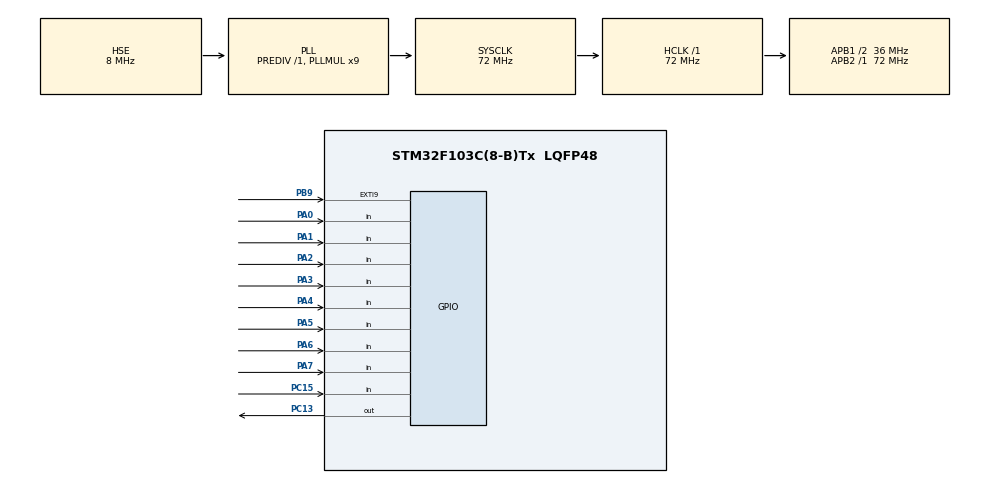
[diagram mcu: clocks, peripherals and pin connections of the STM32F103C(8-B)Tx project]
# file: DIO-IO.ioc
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Mcu.Family=STM32F1
Mcu.Name=STM32F103C(8-B)Tx
Mcu.Package=LQFP48
NVIC.EXTI9_5_IRQn=true\:0\:0\:false\:false\:true\:true\:true\:true
NVIC.PriorityGroup=NVIC_PRIORITYGROUP_4
PA0-WKUP.GPIO_PuPd=GPIO_PULLDOWN
PA0-WKUP.Signal=GPIO_Input
PA1.GPIO_PuPd=GPIO_PULLDOWN
PA1.Signal=GPIO_Input
PA13.Mode=Serial_Wire
PA13.Signal=SYS_JTMS-SWDIO
PA14.Mode=Serial_Wire
PA14.Signal=SYS_JTCK-SWCLK
PA2.GPIO_PuPd=GPIO_PULLDOWN
PA2.Signal=GPIO_Input
PA3.GPIO_PuPd=GPIO_PULLDOWN
PA3.Signal=GPIO_Input
PA4.GPIO_PuPd=GPIO_PULLDOWN
PA4.Signal=GPIO_Input
PA5.GPIO_PuPd=GPIO_PULLDOWN
PA5.Signal=GPIO_Input
PA6.GPIO_PuPd=GPIO_PULLDOWN
PA6.Signal=GPIO_Input
PA7.GPIO_PuPd=GPIO_PULLDOWN
PA7.Signal=GPIO_Input
PB9.GPIO_ModeDefaultEXTI=GPIO_MODE_IT_RISING
PB9.GPIO_PuPd=GPIO_PULLDOWN
PB9.Signal=GPXTI9
PC13-TAMPER-RTC.GPIO_PuPd=GPIO_NOPULL
PC13-TAMPER-RTC.Signal=GPIO_Output
PC15-OSC32_OUT.GPIO_PuPd=GPIO_PULLDOWN
PC15-OSC32_OUT.Signal=GPIO_Input
PD0-OSC_IN.Mode=HSE-External-Oscillator
PD0-OSC_IN.Signal=RCC_OSC_IN
PD1-OSC_OUT.Mode=HSE-External-Oscillator
PD1-OSC_OUT.Signal=RCC_OSC_OUT
ProjectManager.HeapSize=0x200
ProjectManager.StackSize=0x400
ProjectManager.TargetToolchain=CMake
RCC.AHBFreq_Value=72000000
RCC.APB1CLKDivider=RCC_HCLK_DIV2
RCC.APB1Freq_Value=36000000
RCC.APB1TimFreq_Value=72000000
RCC.APB2Freq_Value=72000000
RCC.APB2TimFreq_Value=72000000
RCC.HCLKFreq_Value=72000000
RCC.PLLMUL=RCC_PLL_MUL9
RCC.PLLSourceVirtual=RCC_PLLSOURCE_HSE
RCC.SYSCLKFreq_VALUE=72000000
RCC.SYSCLKSource=RCC_SYSCLKSOURCE_PLLCLK
RCC.USBFreq_Value=72000000
board=custom

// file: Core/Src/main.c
/* USER CODE BEGIN Header */
/**
  ******************************************************************************
  * @file           : main.c
  * @brief          : Main program body
  ******************************************************************************
  * @attention
  *
  * Copyright (c) 2026 STMicroelectronics.
  * All rights reserved.
  *
  * This software is licensed under terms that can be found in the LICENSE file
  * in the root directory of this software component.
  * If no LICENSE file comes with this software, it is provided AS-IS.
  *
  ******************************************************************************
  */
/* USER CODE END Header */
#include "main.h"

/* USER CODE BEGIN PTD */
uint8_t input_dio[8] = {0};
int poini = 0;
int start=0;
/* USER CODE END PTD */

void SystemClock_Config(void);
static void MX_GPIO_Init(void);

int main(void)
{

  /* MCU Configuration--------------------------------------------------------*/

  /* Reset of all peripherals, Initializes the Flash interface and the Systick. */
  HAL_Init();

  /* Configure the system clock */
  SystemClock_Config();

  /* Initialize all configured peripherals */
  MX_GPIO_Init();

  /* Infinite loop */
  /* USER CODE BEGIN WHILE */
  while (1)
  {

    //input_dio = GPIOA->IDR & 0x00ff;// 中断确实被触�????????

    /* USER CODE END WHILE */

  }
}

void SystemClock_Config(void)
{
  RCC_OscInitTypeDef RCC_OscInitStruct = {0};
  RCC_ClkInitTypeDef RCC_ClkInitStruct = {0};

  /** Initializes the RCC Oscillators according to the specified parameters
  * in the RCC_OscInitTypeDef structure.
  */
  RCC_OscInitStruct.OscillatorType = RCC_OSCILLATORTYPE_HSE;
  RCC_OscInitStruct.HSEState = RCC_HSE_ON;
  RCC_OscInitStruct.HSEPredivValue = RCC_HSE_PREDIV_DIV1;
  RCC_OscInitStruct.HSIState = RCC_HSI_ON;
  RCC_OscInitStruct.PLL.PLLState = RCC_PLL_ON;
  RCC_OscInitStruct.PLL.PLLSource = RCC_PLLSOURCE_HSE;
  RCC_OscInitStruct.PLL.PLLMUL = RCC_PLL_MUL9;
  if (HAL_RCC_OscConfig(&RCC_OscInitStruct) != HAL_OK)
  {
    Error_Handler();
  }

  /** Initializes the CPU, AHB and APB buses clocks
  */
  RCC_ClkInitStruct.ClockType = RCC_CLOCKTYPE_HCLK|RCC_CLOCKTYPE_SYSCLK
                              |RCC_CLOCKTYPE_PCLK1|RCC_CLOCKTYPE_PCLK2;
  RCC_ClkInitStruct.SYSCLKSource = RCC_SYSCLKSOURCE_PLLCLK;
  RCC_ClkInitStruct.AHBCLKDivider = RCC_SYSCLK_DIV1;
  RCC_ClkInitStruct.APB1CLKDivider = RCC_HCLK_DIV2;
  RCC_ClkInitStruct.APB2CLKDivider = RCC_HCLK_DIV1;

  if (HAL_RCC_ClockConfig(&RCC_ClkInitStruct, FLASH_LATENCY_2) != HAL_OK)
  {
    Error_Handler();
  }
}

static void MX_GPIO_Init(void)
{
  GPIO_InitTypeDef GPIO_InitStruct = {0};

  /* GPIO Ports Clock Enable */
  __HAL_RCC_GPIOC_CLK_ENABLE();
  __HAL_RCC_GPIOD_CLK_ENABLE();
  __HAL_RCC_GPIOA_CLK_ENABLE();
  __HAL_RCC_GPIOB_CLK_ENABLE();

  /*Configure GPIO pin Output Level */
  HAL_GPIO_WritePin(GPIOC, GPIO_PIN_13, GPIO_PIN_RESET);

  /*Configure GPIO pin : PC13 */
  GPIO_InitStruct.Pin = GPIO_PIN_13;
  GPIO_InitStruct.Mode = GPIO_MODE_OUTPUT_PP;
  GPIO_InitStruct.Pull = GPIO_NOPULL;
  GPIO_InitStruct.Speed = GPIO_SPEED_FREQ_LOW;
  HAL_GPIO_Init(GPIOC, &GPIO_InitStruct);

  /*Configure GPIO pin : PC15 */
  GPIO_InitStruct.Pin = GPIO_PIN_15;
  GPIO_InitStruct.Mode = GPIO_MODE_INPUT;
  GPIO_InitStruct.Pull = GPIO_PULLDOWN;
  HAL_GPIO_Init(GPIOC, &GPIO_InitStruct);

  /*Configure GPIO pins : PA0 PA1 PA2 PA3
                           PA4 PA5 PA6 PA7 */
  GPIO_InitStruct.Pin = GPIO_PIN_0|GPIO_PIN_1|GPIO_PIN_2|GPIO_PIN_3
                          |GPIO_PIN_4|GPIO_PIN_5|GPIO_PIN_6|GPIO_PIN_7;
  GPIO_InitStruct.Mode = GPIO_MODE_INPUT;
  GPIO_InitStruct.Pull = GPIO_PULLDOWN;
  HAL_GPIO_Init(GPIOA, &GPIO_InitStruct);

  /*Configure GPIO pin : PB9 */
  GPIO_InitStruct.Pin = GPIO_PIN_9;
  GPIO_InitStruct.Mode = GPIO_MODE_IT_RISING;
  GPIO_InitStruct.Pull = GPIO_PULLDOWN;
  HAL_GPIO_Init(GPIOB, &GPIO_InitStruct);

  /* EXTI interrupt init*/
  HAL_NVIC_SetPriority(EXTI9_5_IRQn, 0, 0);
  HAL_NVIC_EnableIRQ(EXTI9_5_IRQn);

}

/* USER CODE BEGIN 4 */
void HAL_GPIO_EXTI_Callback(uint16_t GPIO_Pin)
{
  int input = GPIOA->IDR & 0x00ff;
  if(GPIO_Pin == GPIO_PIN_9)
  {
    if(input == 1 && start == 0)
    {
      start=1;
    }
    if (start == 1)
    {

      input_dio[poini] = input;
      poini++;
      if (poini >= 8)
      {
        poini = 0;
        start=0;
      }
    }

  }
}
/* USER CODE END 4 */

void Error_Handler(void)
{
  __disable_irq();
  while (1)
  {
  }
}
